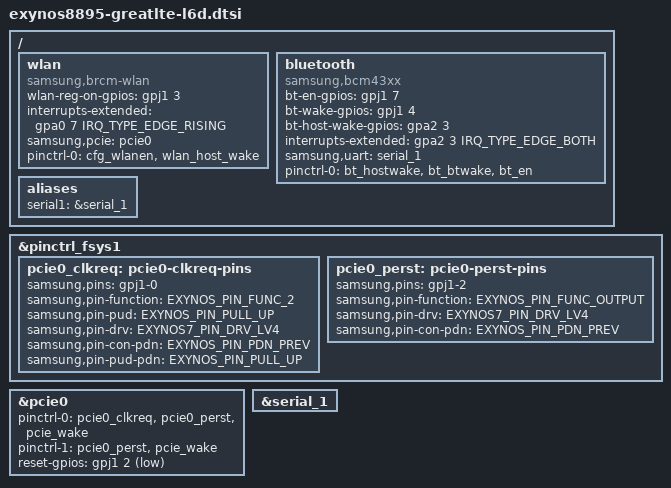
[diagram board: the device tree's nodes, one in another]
// SPDX-License-Identifier: GPL-2.0 OR BSD-3-Clause
/*
 * Samsung Galaxy Note 8 (greatlte, SM-N950N) board DT, part "l6d":
 * L6D connectivity: PCIe Wi-Fi, Bluetooth, serial1 alias (L6D 4, plan 1.2 X-35).
 *
 * Included at the end of exynos8895-greatlte.dts, after L0's nodes, in the merge
 * order of FULL_IMAGE_PLAN.md 2.2. Owner: WP-6D; no other work package edits this
 * file (plan 2.3 rule D1). A node that two parts both configure (&usi9, &usi10)
 * is written identically in both files: dtc lets the later file win on a differing
 * value, which gl-verify V-DUP reports as an error. L0's reserved-memory stays in
 * the .dts; carveout additions and flag changes are &label edits here (plan X-8).
 */

/* L6D PCIe RC0 (K-F3) */
&pinctrl_fsys1 {
	/* FDT:958-967 pcie0_clkreq (phandle 0x108) */
	pcie0_clkreq: pcie0-clkreq-pins {
		samsung,pins = "gpj1-0";
		samsung,pin-function = <EXYNOS_PIN_FUNC_2>;	/* FDT:960 0x02 */
		samsung,pin-pud = <EXYNOS_PIN_PULL_UP>;		/* FDT:961 0x03; A:.../exynos-pinctrl.h:16 PULL_UP = 3 */
		samsung,pin-drv = <EXYNOS7_PIN_DRV_LV4>;	/* FDT:962 0x03; A:.../exynos-pinctrl.h:51 = 3 (value ACK cfg_wlanen uses in the same bank) */
		samsung,pin-con-pdn = <EXYNOS_PIN_PDN_PREV>;	/* FDT:963 0x03; exynos-pinctrl.h:22 */
		samsung,pin-pud-pdn = <EXYNOS_PIN_PULL_UP>;	/* FDT:964 0x03 */
	};

	/* FDT:979-986 pcie0_perst (phandle 0x109) */
	pcie0_perst: pcie0-perst-pins {
		samsung,pins = "gpj1-2";
		samsung,pin-function = <EXYNOS_PIN_FUNC_OUTPUT>;	/* FDT:981 0x01 */
		samsung,pin-drv = <EXYNOS7_PIN_DRV_LV4>;	/* FDT:982 0x03 */
		samsung,pin-con-pdn = <EXYNOS_PIN_PDN_PREV>;	/* FDT:983 0x03 */
	};
};

&pcie0 {
	pinctrl-names = "default", "clkreq_output";		/* FDT:8225 */
	pinctrl-0 = <&pcie0_clkreq &pcie0_perst &pcie_wake>;	/* FDT:8226 <0x108 0x109 0x10a 0x10b 0x10c>; 0x10b/0x10c (cfg_wlanen,
								 * wlan_host_wake) are claimed by the wlan node only: 6.18 pinmux refuses a
								 * second owner of a muxed pin (pinmux_request "already requested") */
	pinctrl-1 = <&pcie0_perst &pcie_wake>;			/* FDT:8227 <0x109 0x10a 0x10b 0x10c> (clkreq not in this state) */
	reset-gpios = <&gpj1 2 GPIO_ACTIVE_LOW>;		/* PERST#: FDT:8219 gpios = <0x106 0x02 0x01> (0x106 = gpj1, flag 1 = active low) */
	status = "okay";
};

/* L6D Wi-Fi (K-F6, L6D 4.4) */
/ {
	wlan {
		compatible = "samsung,brcm-wlan";		/* FDT:11161 */
		wlan-reg-on-gpios = <&gpj1 3 GPIO_ACTIVE_HIGH>;	/* FDT:11162 gpios[0] = <0x106 0x03 0x01>;
								 * stock drives raw level (S:.../dhd_custom_exynos.c:131,232) */
		interrupts-extended = <&gpa0 7 IRQ_TYPE_EDGE_RISING>;	/* WLAN_HOST_WAKE: FDT:11162 gpios[1] =
								 * <0x90 0x07 0x01> (0x90 = gpa0); rising edge =
								 * IORESOURCE_IRQ_HIGHEDGE, S:.../dhd_custom_exynos.c:303-305 */
		samsung,pcie = <&pcie0>;			/* new: the RC this module hangs off
							 * (stock: SAMSUNG_PCIE_CH_NUM 0, :96-98) */
		pinctrl-names = "default";
		pinctrl-0 = <&cfg_wlanen &wlan_host_wake>;	/* FDT:11163-11164 <0x10b 0x10c> */
		status = "okay";				/* FDT:11165 */
	};
};

/* L6D slice bt */
/ {
	bluetooth {
		compatible = "samsung,bcm43xx";				/* FDT:11976 */
		bt-en-gpios = <&gpj1 7 GPIO_ACTIVE_HIGH>;		/* FDT:11977 gpios[0] = <0x106 0x07 0x00>; S:drivers/bluetooth/bcm43xx.c:274 */
		bt-wake-gpios = <&gpj1 4 GPIO_ACTIVE_HIGH>;		/* gpios[1] = <0x106 0x04 0x00>; :288 */
		bt-host-wake-gpios = <&gpa2 3 GPIO_ACTIVE_HIGH>;	/* BT_HOST_WAKE gpios[2] = <0x4f 0x03 0x0f> (0x4f = gpa2); level read in
									 * the ISR as stock (:303-317, gpio_get_value in :204-234); the
									 * Exynos EINT chip has no irq_get_irqchip_state (RL-11) */
		interrupts-extended = <&gpa2 3 IRQ_TYPE_EDGE_BOTH>;	/* same pin as IRQ (= gpiod_to_irq mapping, samsung_gpio_to_irq
									 * A:drivers/pinctrl/samsung/pinctrl-samsung.c:712); stock requests rising
									 * and flips the edge in the ISR (:212, :255); both edges = same events;
									 * kept so heartbeat row `btw` (HB_IRQ idx 0) resolves; both-edge EINT
									 * trigger exists: A:drivers/pinctrl/samsung/pinctrl-exynos.c:171-172 */
		samsung,uart = <&serial_1>;				/* new: the UART whose TX asserts BT_WAKE (stock BT_UPORT 1, :46) */
		pinctrl-names = "default";
		pinctrl-0 = <&bt_hostwake &bt_btwake &bt_en>;		/* FDT:11978-11979 <0x15a 0x15b 0x15c> */
		status = "okay";					/* FDT:11980 */
	};

	aliases {
		serial1 = &serial_1;		/* (final, R3-10) stock FDT:4156 uart1 = "/uart@10830000"; 6.18 samsung_tty takes
						 * the port index only from the "serial" stem (A:drivers/tty/serial/samsung_tty.c:1961) */
	};
};

&serial_1 {
	status = "okay";			/* FDT:4802; ACK node A:.../exynos8895.dtsi:536-547 already has SPI 389 (FDT:4795 0x185),
						 * uart1_bus pins (FDT:4797 -> 0x27), fifo 256 (FDT:4793) */
};
